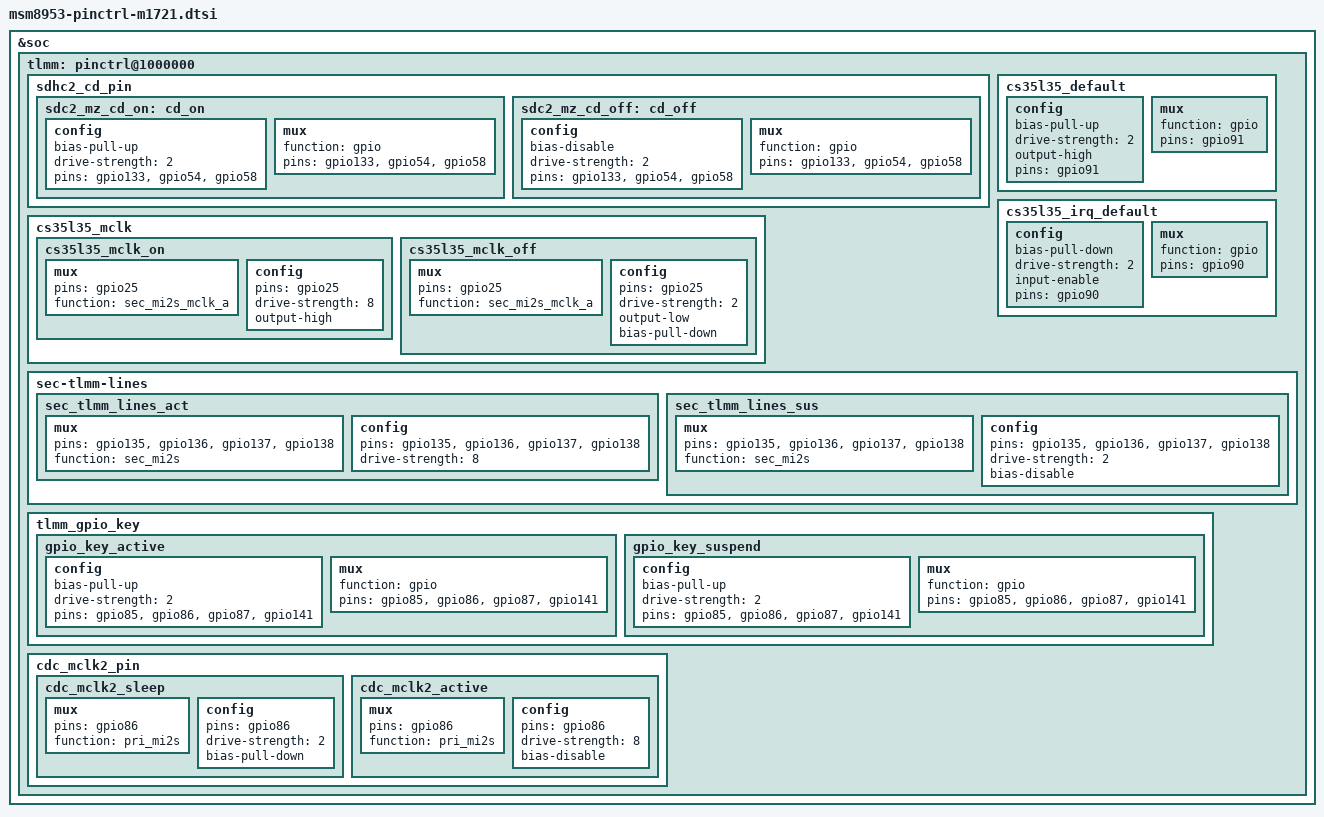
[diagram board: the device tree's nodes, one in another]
/*
 * Copyright (c) 2017, The Linux Foundation. All rights reserved.
 *
 * This program is free software; you can redistribute it and/or modify
 * it under the terms of the GNU General Public License version 2 and
 * only version 2 as published by the Free Software Foundation.
 *
 * This program is distributed in the hope that it will be useful,
 * but WITHOUT ANY WARRANTY; without even the implied warranty of
 * MERCHANTABILITY or FITNESS FOR A PARTICULAR PURPOSE.  See the
 * GNU General Public License for more details.
 */

&soc {

        tlmm: pinctrl@1000000 {
                sdhc2_cd_pin {
                        sdc2_mz_cd_on: cd_on {
                                config {
                                        bias-pull-up;
                                        drive-strength = <2>;
                                        pins = "gpio133", "gpio54", "gpio58";
                                };

                                mux {
                                        function = "gpio";
                                        pins = "gpio133", "gpio54", "gpio58";
                                };
                        };

                        sdc2_mz_cd_off: cd_off {
                                config {
                                        bias-disable;
                                        drive-strength = <2>;
                                        pins = "gpio133", "gpio54", "gpio58";
                                };

                                mux {
                                        function = "gpio";
                                        pins = "gpio133", "gpio54", "gpio58";
                                };
                        };
                };

                // CS35L35 (Audio amplifier for main speaker) part
                cs35l35_default {
                        config {
                                bias-pull-up;
                                drive-strength = <2>;
                                output-high;
                                pins = "gpio91";
                        };

                        mux {
                                function = "gpio";
                                pins = "gpio91";
                        };
                };

                cs35l35_irq_default: cs35l35_irq_default {
                        config {
                                bias-pull-down;
                                drive-strength = <2>;
                                input-enable;
                                pins = "gpio90";
                        };

                        mux {
                                function = "gpio";
                                pins = "gpio90";
                        };
                };

                cs35l35_mclk {

                        cs35l35_mclk_on: cs35l35_mclk_on {

                                mux {
                                        pins = "gpio25";
                                        function = "sec_mi2s_mclk_a";
                                };

                                config {
                                        pins = "gpio25";
                                        drive-strength = <8>;
                                        output-high;
                                };

                        };

                        cs35l35_mclk_off: cs35l35_mclk_off {

                                mux {
                                        pins = "gpio25";
                                        function = "sec_mi2s_mclk_a";
                                };

                                config {
                                        pins = "gpio25";
                                        drive-strength = <2>;
                                        output-low;
                                        bias-pull-down;
                                };

                        };

                };

                sec-tlmm-lines {

                        sec_tlmm_lines_act: sec_tlmm_lines_act {

                                mux {
                                        pins = "gpio135", "gpio136", "gpio137", "gpio138";
                                        function = "sec_mi2s";
                                };

                                config {
                                        pins = "gpio135", "gpio136", "gpio137", "gpio138";
                                        drive-strength = <8>;
                                };

                        };

                        sec_tlmm_lines_sus: sec_tlmm_lines_sus {

                                mux {
                                        pins = "gpio135", "gpio136", "gpio137", "gpio138";
                                        function = "sec_mi2s";
                                };

                                config {
                                        pins = "gpio135", "gpio136", "gpio137", "gpio138";
                                        drive-strength = <2>;
                                        bias-disable;
                                };

                        };

                };

                /delete-node/ tlmm_gpio_key;
                /delete-node/ cdc_mclk2_pin;

                tlmm_gpio_key {
                        gpio_key_active: gpio_key_active {
                                config {
                                        bias-pull-up;
                                        drive-strength = <2>;
                                        pins = "gpio85", "gpio86", "gpio87", "gpio141";
                                };

                                mux {
                                        function = "gpio";
                                        pins = "gpio85", "gpio86", "gpio87", "gpio141";
                                };
                        };

                        gpio_key_suspend: gpio_key_suspend {
                                config {
                                        bias-pull-up;
                                        drive-strength = <2>;
                                        pins = "gpio85", "gpio86", "gpio87", "gpio141";
                                };

                                mux {
                                        function = "gpio";
                                        pins = "gpio85", "gpio86", "gpio87", "gpio141";
                                };
                        };
                };

                cdc_mclk2_pin {
			cdc_mclk2_sleep: cdc_mclk2_sleep {
				mux {
					pins = "gpio86";
					function = "pri_mi2s";
				};
				config {
					pins = "gpio86";
					drive-strength = <2>; /* 2 mA */
					bias-pull-down;       /* PULL DOWN */
				};
			};
			cdc_mclk2_active: cdc_mclk2_active {
				mux {
					pins = "gpio86";
					function = "pri_mi2s";
				};
				config {
					pins = "gpio86";
					drive-strength = <8>; /* 8 mA */
					bias-disable;         /* NO PULL */
				};
			};
		};

        };

};

